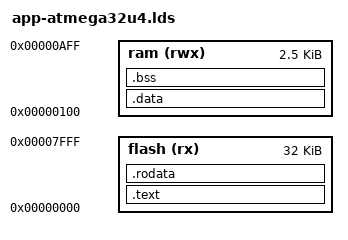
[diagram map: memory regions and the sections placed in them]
/*
 * Copyright (c) 2015-2016, Stuart Wheater, Newcastle upon Tyne, England. All rights reserved.
 */

MEMORY
{
	flash (rx)  : ORIGIN = 0x0000, LENGTH = 32K
	ram   (rwx) : ORIGIN = 0x0100, LENGTH = 2560
}

SECTIONS
{
	.text :
	{
		* (.text);
	} > flash
	.rodata :
	{
		* (.rodata);
	} > flash
	.data :
	{
		* (.data);
	} > ram
	.bss :
	{
		* (.bss);
	} > ram
}
